# G32R501 register map
Vendor: Geehy Semiconductor Co., Ltd.; Series: G32R5; File version: 1.0
CPU: CM55 r0p1, little endian, MPU, FPU, double-precision FPU, DSP, VTOR, 4 interrupt priority bits
Registers are 32-bit, read-write, reset 0x0 unless marked. A register's access mark holds for its fields unless they carry their own. Offsets are from the block's base; [hi:lo] are bit positions; {n}, {i} and the like mark numbered series.

## FLB_XBAR — FLB X-BAR (XBAR_FLB)
Base 0x40031240
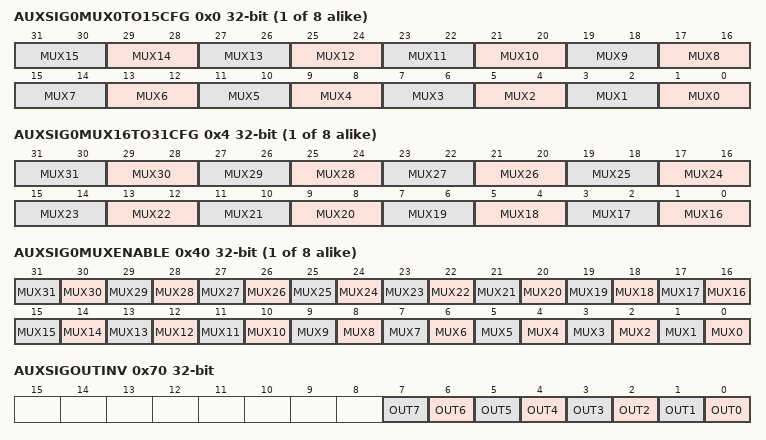
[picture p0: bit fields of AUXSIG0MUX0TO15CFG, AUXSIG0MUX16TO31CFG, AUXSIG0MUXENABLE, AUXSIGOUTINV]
{0x0+8i} AUXSIG{i}MUX0TO15CFG (i=0..7) — FLB XBAR Mux Configuration for Output-{i}
  [2n+1:2n] MUX{n} (n=0..15) — MUX{n} Configuration for AUXSIG{i} of FLB-XBAR
{0x4+8i} AUXSIG{i}MUX16TO31CFG (i=0..7) — FLB XBAR Mux Configuration for Output-{i}
  [2n-31:2n-32] MUX{n} (n=16..31) — MUX{n} Configuration for AUXSIG{i} of FLB-XBAR
{0x40+4i} AUXSIG{i}MUXENABLE (i=0..7) — FLB XBAR Mux Enable Register for Output-{i}
  [n] MUX{n} (n=0..31) — MUX{n} drive for AUXSIG{i} of FLB-XBAR
0x70 AUXSIGOUTINV — FLB XBAR Output Inversion Register
  [n] OUT{n} (n=0..7) — Selects polarity for AUXSIG{n} of FLB-XBAR
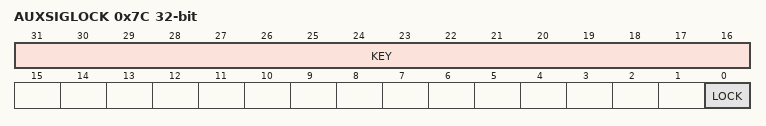
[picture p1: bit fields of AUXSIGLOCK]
0x7C AUXSIGLOCK access per field — FLBXbar Configuration Lock register
  [31:16] KEY rw — Write Protection KEY
  [0] LOCK rw-once — Locks the configuration for FLB-XBAR

## OUTPUT_XBAR — GPIO Output X-BAR (XBAR_OUTPUT)
Base 0x400312C0
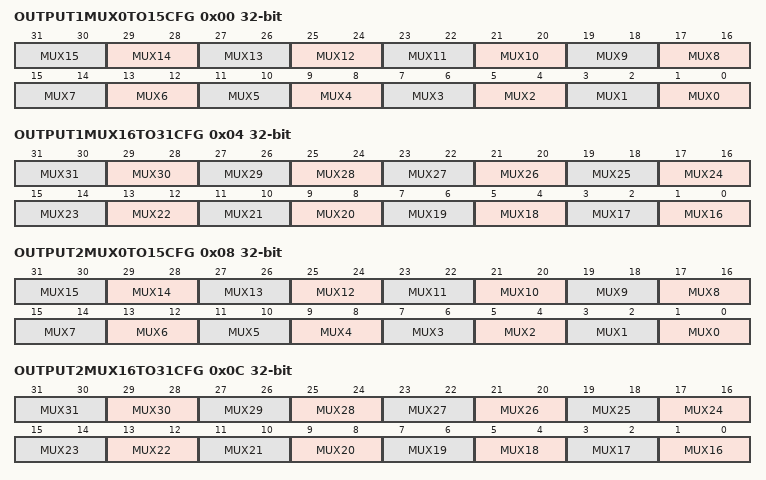
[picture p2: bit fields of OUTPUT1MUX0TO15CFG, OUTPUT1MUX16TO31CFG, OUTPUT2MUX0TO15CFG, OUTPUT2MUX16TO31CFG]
0x00 OUTPUT1MUX0TO15CFG — Output X-BAR Mux Configuration for Output 1
  [2n+1:2n] MUX{n} (n=0..15) — MUX{n} Configuration for OUTPUT1 of OUTPUT-XBAR
0x04 OUTPUT1MUX16TO31CFG — Output X-BAR Mux Configuration for Output 1
  [2n-31:2n-32] MUX{n} (n=16..31) — MUX{n} Configuration for OUTPUT1 of OUTPUT-XBAR
0x08 OUTPUT2MUX0TO15CFG — Output X-BAR Mux Configuration for Output 2
  [2n+1:2n] MUX{n} (n=0..15) — MUX{n} Configuration for OUTPUT2 of OUTPUT-XBAR
0x0C OUTPUT2MUX16TO31CFG — Output X-BAR Mux Configuration for Output 2
  [2n-31:2n-32] MUX{n} (n=16..31) — MUX{n} Configuration for OUTPUT2 of OUTPUT-XBAR
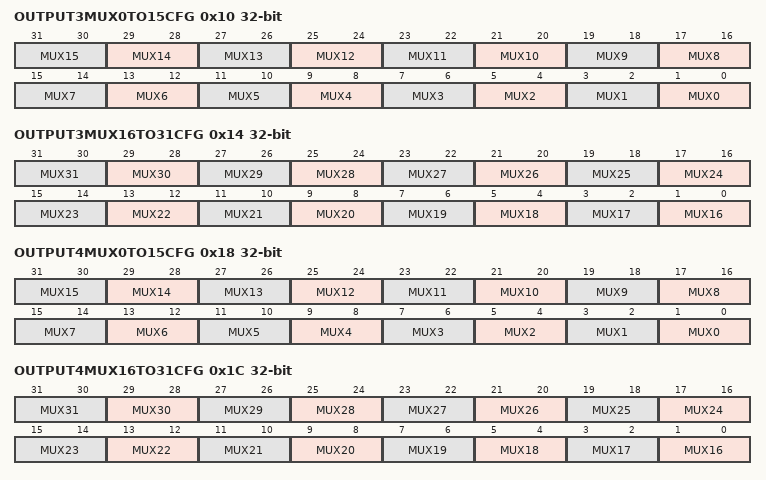
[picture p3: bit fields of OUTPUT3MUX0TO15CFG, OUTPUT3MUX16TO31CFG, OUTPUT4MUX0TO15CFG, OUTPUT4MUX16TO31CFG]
0x10 OUTPUT3MUX0TO15CFG — Output X-BAR Mux Configuration for Output 3
  [2n+1:2n] MUX{n} (n=0..15) — MUX{n} Configuration for OUTPUT3 of OUTPUT-XBAR
0x14 OUTPUT3MUX16TO31CFG — Output X-BAR Mux Configuration for Output 3
  [2n-31:2n-32] MUX{n} (n=16..31) — MUX{n} Configuration for OUTPUT3 of OUTPUT-XBAR
0x18 OUTPUT4MUX0TO15CFG — Output X-BAR Mux Configuration for Output 4
  [2n+1:2n] MUX{n} (n=0..15) — MUX{n} Configuration for OUTPUT4 of OUTPUT-XBAR
0x1C OUTPUT4MUX16TO31CFG — Output X-BAR Mux Configuration for Output 4
  [2n-31:2n-32] MUX{n} (n=16..31) — MUX{n} Configuration for OUTPUT4 of OUTPUT-XBAR
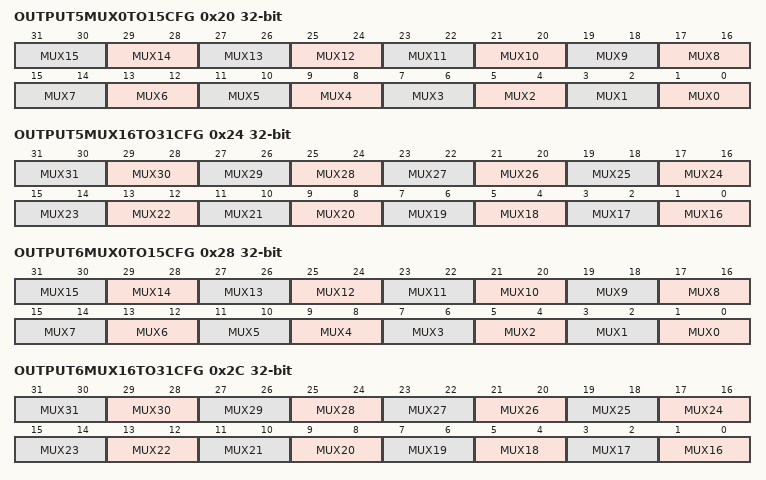
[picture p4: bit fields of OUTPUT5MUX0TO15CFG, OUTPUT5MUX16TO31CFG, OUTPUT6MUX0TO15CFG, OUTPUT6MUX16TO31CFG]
0x20 OUTPUT5MUX0TO15CFG — Output X-BAR Mux Configuration for Output 5
  [2n+1:2n] MUX{n} (n=0..15) — MUX{n} Configuration for OUTPUT5 of OUTPUT-XBAR
0x24 OUTPUT5MUX16TO31CFG — Output X-BAR Mux Configuration for Output 5
  [2n-31:2n-32] MUX{n} (n=16..31) — MUX{n} Configuration for OUTPUT5 of OUTPUT-XBAR
0x28 OUTPUT6MUX0TO15CFG — Output X-BAR Mux Configuration for Output 6
  [2n+1:2n] MUX{n} (n=0..15) — MUX{n} Configuration for OUTPUT6 of OUTPUT-XBAR
0x2C OUTPUT6MUX16TO31CFG — Output X-BAR Mux Configuration for Output 6
  [2n-31:2n-32] MUX{n} (n=16..31) — MUX{n} Configuration for OUTPUT6 of OUTPUT-XBAR
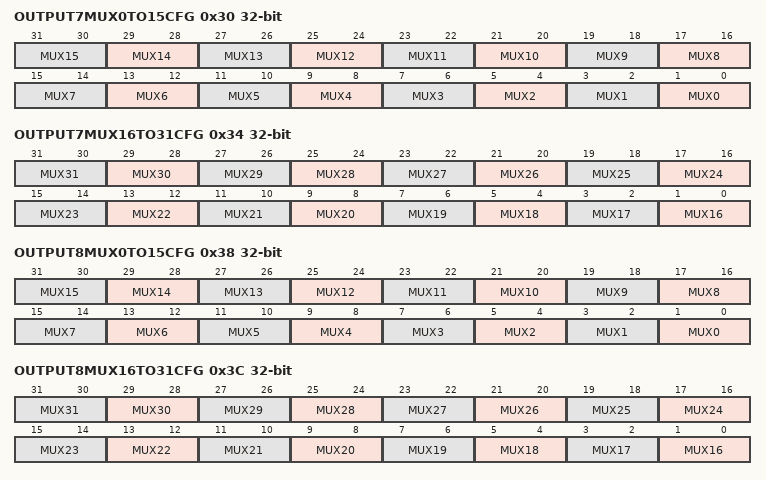
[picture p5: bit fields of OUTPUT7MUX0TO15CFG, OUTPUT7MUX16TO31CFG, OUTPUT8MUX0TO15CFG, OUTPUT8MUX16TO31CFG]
0x30 OUTPUT7MUX0TO15CFG — Output X-BAR Mux Configuration for Output 7
  [2n+1:2n] MUX{n} (n=0..15) — MUX{n} Configuration for OUTPUT7 of OUTPUT-XBAR
0x34 OUTPUT7MUX16TO31CFG — Output X-BAR Mux Configuration for Output 7
  [2n-31:2n-32] MUX{n} (n=16..31) — MUX{n} Configuration for OUTPUT7 of OUTPUT-XBAR
0x38 OUTPUT8MUX0TO15CFG — Output X-BAR Mux Configuration for Output 8
  [2n+1:2n] MUX{n} (n=0..15) — MUX{n} Configuration for OUTPUT8 of OUTPUT-XBAR
0x3C OUTPUT8MUX16TO31CFG — Output X-BAR Mux Configuration for Output 8
  [2n-31:2n-32] MUX{n} (n=16..31) — MUX{n} Configuration for OUTPUT8 of OUTPUT-XBAR
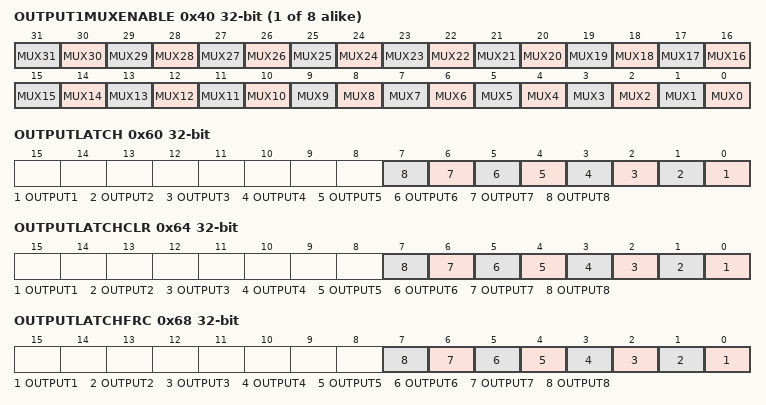
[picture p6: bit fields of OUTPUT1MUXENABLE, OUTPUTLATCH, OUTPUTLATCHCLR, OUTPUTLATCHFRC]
{0x3C+4i} OUTPUT{i}MUXENABLE (i=1..8) — Output X-BAR Mux Enable for Output {i}
  [n] MUX{n} (n=0..31) — MUX{n} drive for OUTPUT{i} of OUTPUT-XBAR
0x60 OUTPUTLATCH ro — Output X-BAR Output Latch
  [n-1] OUTPUT{n} (n=1..8) — Records the OUTPUT{n} of OUTPUT-XBAR
0x64 OUTPUTLATCHCLR — Output X-BAR Output Latch Clear
  [n-1] OUTPUT{n} (n=1..8) — Clears the Output-Latch for OUTPUT{n} of OUTPUT-XBAR
0x68 OUTPUTLATCHFRC — Output X-BAR Output Latch Clear
  [n-1] OUTPUT{n} (n=1..8) — Sets the Output-Latch for OUTPUT{n} of OUTPUT-XBAR
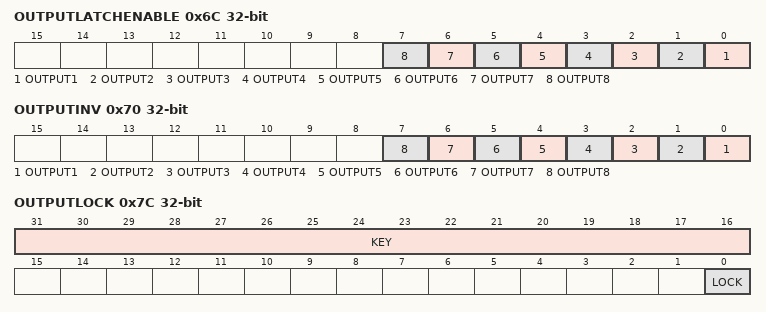
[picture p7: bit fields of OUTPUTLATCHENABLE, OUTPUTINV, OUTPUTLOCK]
0x6C OUTPUTLATCHENABLE — Output X-BAR Output Latch Enable
  [n-1] OUTPUT{n} (n=1..8) — Selects the output latch to drive OUTPUT{n} of OUTPUT-XBAR
0x70 OUTPUTINV — Output X-BAR Output Inversion
  [n-1] OUTPUT{n} (n=1..8) — Selects polarity for OUTPUT{n} of OUTPUT-XBAR
0x7C OUTPUTLOCK — Output X-BAR Configuration Lock register
  [31:16] KEY — Write Protection KEY
  [0] LOCK rw-once — Locks the configuration for OUTPUT-XBAR
